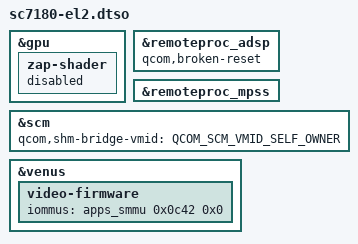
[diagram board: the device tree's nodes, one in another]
// SPDX-License-Identifier: BSD-3-Clause
#include <dt-bindings/firmware/qcom,scm.h>

/*
 * sc7180 specific modifications required to boot in EL2.
 */

/dts-v1/;
/plugin/;

/* We can't and don't need to use zap shader in EL2 as linux can zap the gpu on it's own. */
&gpu {
	zap-shader {
		status = "disabled";
	};
};

&remoteproc_adsp {
	qcom,broken-reset;
};

&remoteproc_mpss {
	/* Reset is implemented in TZ firmware, so no qcom,broken-reset here */
};

&scm {
	qcom,shm-bridge-vmid = <QCOM_SCM_VMID_SELF_OWNER>;
};

/* Venus can be used in EL2 if booted similarly to ChromeOS devices. */
&venus {
	video-firmware {
		iommus = <&apps_smmu 0x0c42 0x0>;
	};
};
